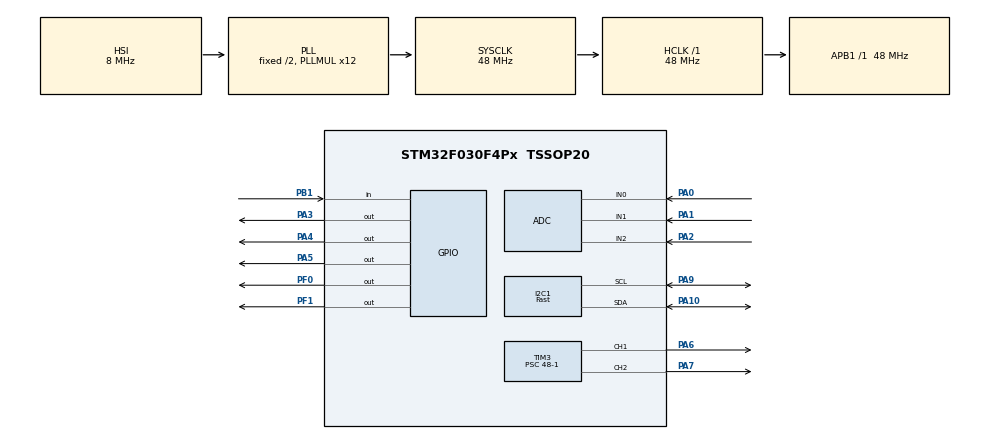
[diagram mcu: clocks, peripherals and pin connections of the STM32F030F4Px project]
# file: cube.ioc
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ADC.DMAContinuousRequests=ENABLE
ADC.EOCSelection=ADC_EOC_SEQ_CONV
ADC.ExternalTrigConv=ADC_EXTERNALTRIGCONV_T1_CC4
ADC.ExternalTrigConvEdge=ADC_EXTERNALTRIGCONVEDGE_RISING
ADC.LowPowerAutoWait=DISABLE
ADC.Overrun=ADC_OVR_DATA_OVERWRITTEN
ADC.SamplingTime=ADC_SAMPLETIME_41CYCLES_5
Dma.ADC.0.Direction=DMA_PERIPH_TO_MEMORY
Dma.ADC.0.Instance=DMA1_Channel1
Dma.ADC.0.MemDataAlignment=DMA_MDATAALIGN_HALFWORD
Dma.ADC.0.MemInc=DMA_MINC_ENABLE
Dma.ADC.0.Mode=DMA_CIRCULAR
Dma.ADC.0.PeriphDataAlignment=DMA_PDATAALIGN_HALFWORD
Dma.ADC.0.PeriphInc=DMA_PINC_DISABLE
Dma.ADC.0.Priority=DMA_PRIORITY_HIGH
Dma.Request0=ADC
I2C1.I2C_Fall_Time=300
I2C1.I2C_Rise_Time=300
I2C1.I2C_Speed_Mode=I2C_Fast
I2C1.Timing=0x00300208
Mcu.Family=STM32F0
Mcu.Name=STM32F030F4Px
Mcu.Package=TSSOP20
NVIC.DMA1_Channel1_IRQn=true\:0\:0\:false\:false\:true\:false\:true
NVIC.I2C1_IRQn=true\:0\:0\:false\:false\:true\:true\:true
PA0.Mode=IN0
PA0.Signal=ADC_IN0
PA1.Mode=IN1
PA1.Signal=ADC_IN1
PA10.Mode=I2C
PA10.Signal=I2C1_SDA
PA13.Mode=Serial_Wire
PA13.Signal=SYS_SWDIO
PA14.Mode=Serial_Wire
PA14.Signal=SYS_SWCLK
PA2.Mode=IN2
PA2.Signal=ADC_IN2
PA3.GPIO_Speed=GPIO_SPEED_FREQ_MEDIUM
PA3.Signal=GPIO_Output
PA4.GPIO_Speed=GPIO_SPEED_FREQ_MEDIUM
PA4.Signal=GPIO_Output
PA5.Signal=GPIO_Output
PA6.Signal=S_TIM3_CH1
PA7.Signal=S_TIM3_CH2
PA9.Mode=I2C
PA9.Signal=I2C1_SCL
PB1.GPIO_PuPd=GPIO_PULLUP
PB1.Signal=GPIO_Input
PF0-OSC_IN.GPIO_Speed=GPIO_SPEED_FREQ_MEDIUM
PF0-OSC_IN.Signal=GPIO_Output
PF1-OSC_OUT.GPIO_Speed=GPIO_SPEED_FREQ_MEDIUM
PF1-OSC_OUT.Signal=GPIO_Output
ProjectManager.HeapSize=0x00
ProjectManager.StackSize=0x200
ProjectManager.TargetToolchain=MDK-ARM V5.27
RCC.AHBFreq_Value=48000000
RCC.APB1Freq_Value=48000000
RCC.APB1TimFreq_Value=48000000
RCC.HCLKFreq_Value=48000000
RCC.PLLMUL=RCC_PLL_MUL12
RCC.SYSCLKFreq_VALUE=48000000
RCC.SYSCLKSource=RCC_SYSCLKSOURCE_PLLCLK
SH.S_TIM3_CH1.0=TIM3_CH1,PWM Generation1 CH1
SH.S_TIM3_CH2.0=TIM3_CH2,PWM Generation2 CH2
TIM1.AutoReloadPreload=TIM_AUTORELOAD_PRELOAD_ENABLE
TIM1.Channel-PWM\ Generation4\ No\ Output=TIM_CHANNEL_4
TIM1.Period=0xFFFF
TIM1.Prescaler=48-1
TIM1.Pulse-PWM\ Generation4\ No\ Output=10
TIM1.TIM_MasterOutputTrigger=TIM_TRGO_OC4REF
TIM3.AutoReloadPreload=TIM_AUTORELOAD_PRELOAD_ENABLE
TIM3.Channel-PWM\ Generation1\ CH1=TIM_CHANNEL_1
TIM3.Channel-PWM\ Generation2\ CH2=TIM_CHANNEL_2
TIM3.Period=1000
TIM3.Prescaler=48-1
VP_TIM1_VS_no_output4.Mode=PWM Generation4 No Output
board=custom

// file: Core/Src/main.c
/* USER CODE BEGIN Header */
/**
  ******************************************************************************
  * @file           : main.c
  * @brief          : Main program body
  ******************************************************************************
  * @attention
  *
  * <h2><center>&copy; Copyright (c) 2020 STMicroelectronics.
  * All rights reserved.</center></h2>
  *
  * This software component is licensed by ST under BSD 3-Clause license,
  * the "License"; You may not use this file except in compliance with the
  * License. You may obtain a copy of the License at:
  *                        opensource.org/licenses/BSD-3-Clause
  *
  ******************************************************************************
  */
/* USER CODE END Header */

#include "main.h"
#include "adc.h"
#include "dma.h"
#include "i2c.h"
#include "tim.h"
#include "gpio.h"

/* USER CODE BEGIN Includes */
#include "user.h"
/* USER CODE END Includes */

void SystemClock_Config(void);

int main(void)
{

  /* MCU Configuration--------------------------------------------------------*/

  /* Reset of all peripherals, Initializes the Flash interface and the Systick. */
  HAL_Init();

  /* Configure the system clock */
  SystemClock_Config();

  /* Initialize all configured peripherals */
  MX_GPIO_Init();
  MX_DMA_Init();
  MX_ADC_Init();
  MX_I2C1_Init();
  MX_TIM1_Init();
  MX_TIM3_Init();

  /* Infinite loop */
  while (1)
  {
		user_loop();
  }
}

void SystemClock_Config(void)
{
  RCC_OscInitTypeDef RCC_OscInitStruct = {0};
  RCC_ClkInitTypeDef RCC_ClkInitStruct = {0};
  RCC_PeriphCLKInitTypeDef PeriphClkInit = {0};

  /** Initializes the CPU, AHB and APB busses clocks
  */
  RCC_OscInitStruct.OscillatorType = RCC_OSCILLATORTYPE_HSI|RCC_OSCILLATORTYPE_HSI14;
  RCC_OscInitStruct.HSIState = RCC_HSI_ON;
  RCC_OscInitStruct.HSI14State = RCC_HSI14_ON;
  RCC_OscInitStruct.HSICalibrationValue = RCC_HSICALIBRATION_DEFAULT;
  RCC_OscInitStruct.HSI14CalibrationValue = 16;
  RCC_OscInitStruct.PLL.PLLState = RCC_PLL_ON;
  RCC_OscInitStruct.PLL.PLLSource = RCC_PLLSOURCE_HSI;
  RCC_OscInitStruct.PLL.PLLMUL = RCC_PLL_MUL12;
  RCC_OscInitStruct.PLL.PREDIV = RCC_PREDIV_DIV1;
  if (HAL_RCC_OscConfig(&RCC_OscInitStruct) != HAL_OK)
  {
    Error_Handler();
  }
  /** Initializes the CPU, AHB and APB busses clocks
  */
  RCC_ClkInitStruct.ClockType = RCC_CLOCKTYPE_HCLK|RCC_CLOCKTYPE_SYSCLK
                              |RCC_CLOCKTYPE_PCLK1;
  RCC_ClkInitStruct.SYSCLKSource = RCC_SYSCLKSOURCE_PLLCLK;
  RCC_ClkInitStruct.AHBCLKDivider = RCC_SYSCLK_DIV1;
  RCC_ClkInitStruct.APB1CLKDivider = RCC_HCLK_DIV1;

  if (HAL_RCC_ClockConfig(&RCC_ClkInitStruct, FLASH_LATENCY_1) != HAL_OK)
  {
    Error_Handler();
  }
  PeriphClkInit.PeriphClockSelection = RCC_PERIPHCLK_I2C1;
  PeriphClkInit.I2c1ClockSelection = RCC_I2C1CLKSOURCE_HSI;
  if (HAL_RCCEx_PeriphCLKConfig(&PeriphClkInit) != HAL_OK)
  {
    Error_Handler();
  }
}

void Error_Handler(void)
{
  /* USER CODE BEGIN Error_Handler_Debug */
  /* Disable interrupts and halt to prevent running with misconfigured hardware */
  __disable_irq();
  while (1)
  {
  }
  /* USER CODE END Error_Handler_Debug */
}

/************************ (C) COPYRIGHT STMicroelectronics *****END OF FILE****/
